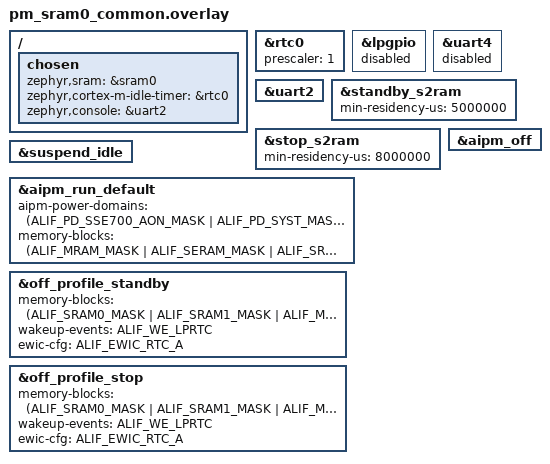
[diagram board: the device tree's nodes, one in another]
/* Copyright (C) 2026 Alif Semiconductor - All Rights Reserved.
 * Use, distribution and modification of this code is permitted under the
 * terms stated in the Alif Semiconductor Software License Agreement
 *
 * You should have received a copy of the Alif Semiconductor Software
 * License Agreement with this file. If not, please write to:
 * contact@alifsemi.com, or visit: https://alifsemi.com/license
 *
 */

/*
 * Common PM S2RAM overlay for SRAM0 retention builds (HE and HP cores).
 *
 * Both cores require a first-stage loader (placed at MRAM before the Zephyr
 * app image) to power up SRAM0 before execution reaches the application.
 * SRAM0 retention masks (ALIF_SRAM0_*_RET_MASK) are Ensemble Gen2 specific.
 */

&rtc0 {
	prescaler = <1>;
	status = "okay";
};

&lpgpio {
	status = "disabled";
};

&uart4 {
	status = "disabled";
};

&uart2 {
	status = "okay";
};

&standby_s2ram {
	min-residency-us = <5000000>;
	status = "okay";
};

&stop_s2ram {
	min-residency-us = <8000000>;
	status = "okay";
};

&suspend_idle {
	status = "okay";
};

&aipm_run_default {
	aipm-power-domains = <(ALIF_PD_SSE700_AON_MASK | ALIF_PD_SYST_MASK)>;
	memory-blocks      = <(ALIF_MRAM_MASK | ALIF_SERAM_MASK |
				ALIF_SRAM0_MASK | ALIF_SRAM1_MASK)>;
};

&aipm_off {
	status = "okay";
};

&off_profile_standby {
	status = "okay";
	memory-blocks = <(ALIF_SRAM0_MASK | ALIF_SRAM1_MASK |
			  ALIF_MRAM_MASK | ALIF_SERAM_MASK |
			  ALIF_SRAM0_1_RET_MASK | ALIF_SRAM0_2_RET_MASK |
			  ALIF_SRAM0_3_RET_MASK | ALIF_SRAM0_4_RET_MASK |
			  ALIF_SRAM1_RET_MASK)>;
	wakeup-events = <ALIF_WE_LPRTC>;
	ewic-cfg      = <ALIF_EWIC_RTC_A>;
};

&off_profile_stop {
	status = "okay";
	memory-blocks = <(ALIF_SRAM0_MASK | ALIF_SRAM1_MASK |
			  ALIF_MRAM_MASK | ALIF_SERAM_MASK |
			  ALIF_SRAM0_1_RET_MASK | ALIF_SRAM0_2_RET_MASK |
			  ALIF_SRAM0_3_RET_MASK | ALIF_SRAM0_4_RET_MASK |
			  ALIF_SRAM1_RET_MASK)>;
	wakeup-events = <ALIF_WE_LPRTC>;
	ewic-cfg      = <ALIF_EWIC_RTC_A>;
};

/ {
	chosen {
		zephyr,sram              = &sram0;
		zephyr,cortex-m-idle-timer = &rtc0;
		zephyr,console           = &uart2;
	};
};
